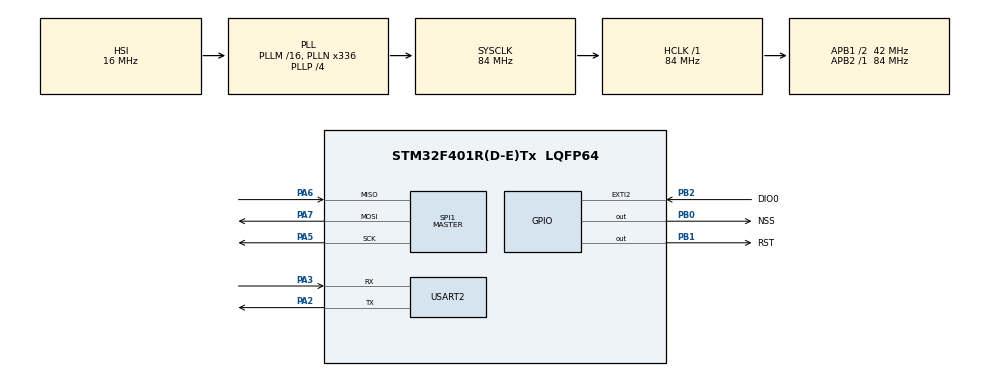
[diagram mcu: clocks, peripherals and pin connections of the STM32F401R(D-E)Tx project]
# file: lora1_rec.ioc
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Mcu.Family=STM32F4
Mcu.Name=STM32F401R(D-E)Tx
Mcu.Package=LQFP64
NVIC.PriorityGroup=NVIC_PRIORITYGROUP_0
PA13.Mode=Serial_Wire
PA13.Signal=SYS_JTMS-SWDIO
PA14.Mode=Serial_Wire
PA14.Signal=SYS_JTCK-SWCLK
PA2.Mode=Asynchronous
PA2.Signal=USART2_TX
PA3.Mode=Asynchronous
PA3.Signal=USART2_RX
PA5.Mode=Full_Duplex_Master
PA5.Signal=SPI1_SCK
PA6.Mode=Full_Duplex_Master
PA6.Signal=SPI1_MISO
PA7.Mode=Full_Duplex_Master
PA7.Signal=SPI1_MOSI
PB0.GPIO_Label=NSS
PB0.PinState=GPIO_PIN_SET
PB0.Signal=GPIO_Output
PB1.GPIO_Label=RST
PB1.PinState=GPIO_PIN_SET
PB1.Signal=GPIO_Output
PB2.GPIO_Label=DIO0
PB2.Signal=GPXTI2
PH0\ -\ OSC_IN.Mode=HSE-External-Oscillator
PH0\ -\ OSC_IN.Signal=RCC_OSC_IN
PH1\ -\ OSC_OUT.Mode=HSE-External-Oscillator
PH1\ -\ OSC_OUT.Signal=RCC_OSC_OUT
ProjectManager.HeapSize=0x200
ProjectManager.StackSize=0x400
ProjectManager.TargetToolchain=STM32CubeIDE
RCC.48MHZClocksFreq_Value=48000000
RCC.AHBFreq_Value=84000000
RCC.APB1CLKDivider=RCC_HCLK_DIV2
RCC.APB1Freq_Value=42000000
RCC.APB1TimFreq_Value=84000000
RCC.APB2Freq_Value=84000000
RCC.APB2TimFreq_Value=84000000
RCC.CortexFreq_Value=84000000
RCC.HCLKFreq_Value=84000000
RCC.HSE_VALUE=8000000
RCC.HSI_VALUE=16000000
RCC.LSE_VALUE=32768
RCC.PLLN=336
RCC.PLLP=RCC_PLLP_DIV4
RCC.PLLQ=7
RCC.SYSCLKFreq_VALUE=84000000
RCC.SYSCLKSource=RCC_SYSCLKSOURCE_PLLCLK
RCC.VCOOutputFreq_Value=336000000
SPI1.Direction=SPI_DIRECTION_2LINES
SPI1.Mode=SPI_MODE_MASTER
SPI1.VirtualType=VM_MASTER
USART2.VirtualMode=VM_ASYNC
board=NUCLEO-F401RE

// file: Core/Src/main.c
/* USER CODE BEGIN Header */
/**
  ******************************************************************************
  * @file           : main.c
  * @brief          : Main program body
  ******************************************************************************
  * @attention
  *
  * Copyright (c) 2023 STMicroelectronics.
  * All rights reserved.
  *
  * This software is licensed under terms that can be found in the LICENSE file
  * in the root directory of this software component.
  * If no LICENSE file comes with this software, it is provided AS-IS.
  *
  ******************************************************************************
  */
/* USER CODE END Header */
#include "main.h"
#include "spi.h"
#include "usart.h"
#include "gpio.h"
#include "Lora.h"
#include <stdio.h>
#include<string.h>

LoRa myLoRa;
uint8_t rxData[128];

void SystemClock_Config(void);

int main(void)
{
  HAL_Init();
  SystemClock_Config();
  MX_GPIO_Init();
  MX_SPI1_Init();
  MX_USART2_UART_Init();

  myLoRa = newLoRa();

  myLoRa.CS_port         = NSS_GPIO_Port;
  myLoRa.CS_pin          = NSS_Pin;
  myLoRa.reset_port      = RST_GPIO_Port;
  myLoRa.reset_pin       = RST_Pin;
  myLoRa.DIO0_port       = DIO0_GPIO_Port;
  myLoRa.DIO0_pin        = DIO0_Pin;
  myLoRa.hSPIx           = &hspi1;

  myLoRa.frequency             = 440;             // default = 433 MHz
  myLoRa.spredingFactor        = SF_7;            // default = SF_7
  myLoRa.bandWidth             = BW_31_25KHz;      // default = BW_125KHz
  myLoRa.crcRate               = CR_4_5;          // default = CR_4_5
  myLoRa.power                 = POWER_20db;      // default = 20db
  myLoRa.overCurrentProtection = 130;             // default = 100 mA
  myLoRa.preamble              = 9;               // default = 8

  if (LoRa_init(&myLoRa) == LORA_OK)
  {
    LoRa_startReceiving(&myLoRa);
  }

  while (1)
  {
    if (LoRa_receive(&myLoRa, rxData, sizeof(rxData)) == LORA_OK)
    {
      // Process received data
      // Example: Print received data to the console via UART
      HAL_UART_Transmit(&huart2, rxData, strlen((char*)rxData), HAL_MAX_DELAY);
      HAL_UART_Transmit(&huart2, (uint8_t*)"\r\n", 2, HAL_MAX_DELAY);
    }
  }
}
void SystemClock_Config(void)
{
  RCC_OscInitTypeDef RCC_OscInitStruct = {0};
  RCC_ClkInitTypeDef RCC_ClkInitStruct = {0};

  /** Configure the main internal regulator output voltage
  */
  __HAL_RCC_PWR_CLK_ENABLE();
  __HAL_PWR_VOLTAGESCALING_CONFIG(PWR_REGULATOR_VOLTAGE_SCALE2);

  /** Initializes the RCC Oscillators according to the specified parameters
  * in the RCC_OscInitTypeDef structure.
  */
  RCC_OscInitStruct.OscillatorType = RCC_OSCILLATORTYPE_HSI;
  RCC_OscInitStruct.HSIState = RCC_HSI_ON;
  RCC_OscInitStruct.HSICalibrationValue = RCC_HSICALIBRATION_DEFAULT;
  RCC_OscInitStruct.PLL.PLLState = RCC_PLL_ON;
  RCC_OscInitStruct.PLL.PLLSource = RCC_PLLSOURCE_HSI;
  RCC_OscInitStruct.PLL.PLLM = 16;
  RCC_OscInitStruct.PLL.PLLN = 336;
  RCC_OscInitStruct.PLL.PLLP = RCC_PLLP_DIV4;
  RCC_OscInitStruct.PLL.PLLQ = 7;
  if (HAL_RCC_OscConfig(&RCC_OscInitStruct) != HAL_OK)
  {
    Error_Handler();
  }

  /** Initializes the CPU, AHB and APB buses clocks
  */
  RCC_ClkInitStruct.ClockType = RCC_CLOCKTYPE_HCLK|RCC_CLOCKTYPE_SYSCLK
                              |RCC_CLOCKTYPE_PCLK1|RCC_CLOCKTYPE_PCLK2;
  RCC_ClkInitStruct.SYSCLKSource = RCC_SYSCLKSOURCE_PLLCLK;
  RCC_ClkInitStruct.AHBCLKDivider = RCC_SYSCLK_DIV1;
  RCC_ClkInitStruct.APB1CLKDivider = RCC_HCLK_DIV2;
  RCC_ClkInitStruct.APB2CLKDivider = RCC_HCLK_DIV1;

  if (HAL_RCC_ClockConfig(&RCC_ClkInitStruct, FLASH_LATENCY_2) != HAL_OK)
  {
    Error_Handler();
  }
}

/* USER CODE BEGIN 4 */
  void HAL_GPIO_EXTI_Callback(uint16_t GPIO_Pin)
  {
    if (GPIO_Pin == DIO0_Pin)
    {
		LoRa_receive(&myLoRa,rxData,128);
	}

  }
/* USER CODE END 4 */

void Error_Handler(void)
{
  __disable_irq();
  while (1)
  {
  }
}
